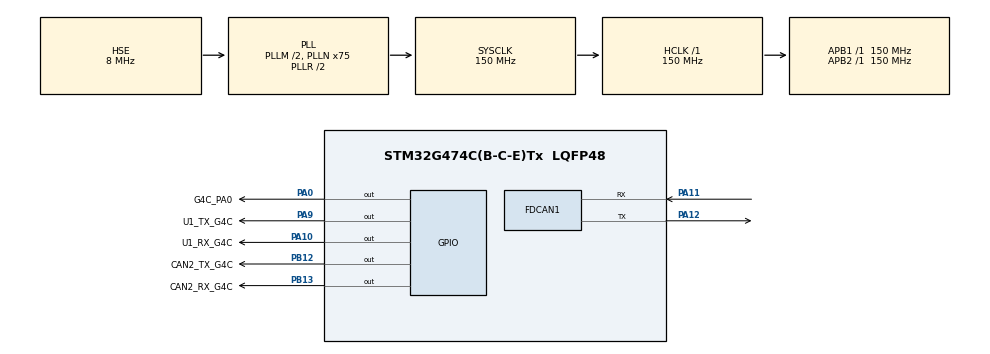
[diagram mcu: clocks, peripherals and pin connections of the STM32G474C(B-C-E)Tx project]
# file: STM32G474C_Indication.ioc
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FDCAN1.AutoRetransmission=DISABLE
FDCAN1.CalculateBaudRateNominal=1000000
FDCAN1.CalculateTimeBitNominal=1000
FDCAN1.CalculateTimeQuantumNominal=100.0
FDCAN1.DataPrescaler=4
FDCAN1.DataSyncJumpWidth=10
FDCAN1.DataTimeSeg1=10
FDCAN1.DataTimeSeg2=5
FDCAN1.ExtFiltersNbr=8
FDCAN1.FrameFormat=FDCAN_FRAME_FD_NO_BRS
FDCAN1.Mode=FDCAN_MODE_NORMAL
FDCAN1.NominalPrescaler=15
FDCAN1.NominalSyncJumpWidth=10
FDCAN1.NominalTimeSeg1=5
FDCAN1.NominalTimeSeg2=4
FDCAN1.StdFiltersNbr=16
Mcu.Family=STM32G4
Mcu.Name=STM32G474C(B-C-E)Tx
Mcu.Package=LQFP48
NVIC.FDCAN1_IT0_IRQn=true\:0\:0\:false\:false\:true\:true\:true\:true
NVIC.FDCAN1_IT1_IRQn=true\:0\:0\:false\:false\:true\:true\:true\:true
NVIC.PriorityGroup=NVIC_PRIORITYGROUP_4
PA0.GPIO_Label=G4C_PA0
PA0.GPIO_Speed=GPIO_SPEED_FREQ_HIGH
PA0.PinState=GPIO_PIN_SET
PA0.Signal=GPIO_Output
PA10.GPIO_Label=U1_RX_G4C
PA10.GPIO_Speed=GPIO_SPEED_FREQ_HIGH
PA10.PinState=GPIO_PIN_SET
PA10.Signal=GPIO_Output
PA11.Mode=FDCAN_Activate
PA11.Signal=FDCAN1_RX
PA12.Mode=FDCAN_Activate
PA12.Signal=FDCAN1_TX
PA13.Mode=Serial_Wire
PA13.Signal=SYS_JTMS-SWDIO
PA14.Mode=Serial_Wire
PA14.Signal=SYS_JTCK-SWCLK
PA9.GPIO_Label=U1_TX_G4C
PA9.GPIO_Speed=GPIO_SPEED_FREQ_HIGH
PA9.PinState=GPIO_PIN_SET
PA9.Signal=GPIO_Output
PB12.GPIO_Label=CAN2_TX_G4C
PB12.GPIO_Speed=GPIO_SPEED_FREQ_HIGH
PB12.PinState=GPIO_PIN_SET
PB12.Signal=GPIO_Output
PB13.GPIO_Label=CAN2_RX_G4C
PB13.GPIO_Speed=GPIO_SPEED_FREQ_HIGH
PB13.PinState=GPIO_PIN_SET
PB13.Signal=GPIO_Output
PF0-OSC_IN.Mode=HSE-External-Oscillator
PF0-OSC_IN.Signal=RCC_OSC_IN
PF1-OSC_OUT.Mode=HSE-External-Oscillator
PF1-OSC_OUT.Signal=RCC_OSC_OUT
ProjectManager.HeapSize=0x200
ProjectManager.StackSize=0x400
ProjectManager.TargetToolchain=MDK-ARM V5.32
RCC.ADC12Freq_Value=150000000
RCC.ADC345Freq_Value=150000000
RCC.AHBFreq_Value=150000000
RCC.APB1Freq_Value=150000000
RCC.APB1TimFreq_Value=150000000
RCC.APB2Freq_Value=150000000
RCC.APB2TimFreq_Value=150000000
RCC.CortexFreq_Value=150000000
RCC.EXTERNAL_CLOCK_VALUE=12288000
RCC.HCLKFreq_Value=150000000
RCC.HSE_VALUE=8000000
RCC.HSI48_VALUE=48000000
RCC.HSI_VALUE=16000000
RCC.LSE_VALUE=32768
RCC.PLLM=RCC_PLLM_DIV2
RCC.PLLN=75
RCC.PLLSourceVirtual=RCC_PLLSOURCE_HSE
RCC.SYSCLKFreq_VALUE=150000000
RCC.SYSCLKSource=RCC_SYSCLKSOURCE_PLLCLK
RCC.USBFreq_Value=150000000
RCC.VCOOutputFreq_Value=300000000
VP_SYS_VS_DBSignals.Mode=DisableDeadBatterySignals
board=custom

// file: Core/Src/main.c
/* USER CODE BEGIN Header */
/**
  ******************************************************************************
  * @file           : main.c
  * @brief          : Main program body
  ******************************************************************************
  * @attention
  *
  * Copyright (c) 2025 STMicroelectronics.
  * All rights reserved.
  *
  * This software is licensed under terms that can be found in the LICENSE file
  * in the root directory of this software component.
  * If no LICENSE file comes with this software, it is provided AS-IS.
  *
  ******************************************************************************
  */
/* USER CODE END Header */
#include "main.h"
#include "fdcan.h"
#include "gpio.h"

/* USER CODE BEGIN Includes */
#include "can_process.h"

/* USER CODE END Includes */

void SystemClock_Config(void);

int main(void)
{

  /* MCU Configuration--------------------------------------------------------*/

  /* Reset of all peripherals, Initializes the Flash interface and the Systick. */
  HAL_Init();

  /* Configure the system clock */
  SystemClock_Config();

  /* Initialize all configured peripherals */
  MX_GPIO_Init();
  MX_FDCAN1_Init();
  /* USER CODE BEGIN 2 */
  FDCAN1_Config();
  //GPIO初始�?

  HAL_GPIO_WritePin(G4C_PA0_GPIO_Port, G4C_PA0_Pin, GPIO_PIN_SET);//单片机指示灯

  //状�?�指示灯
  HAL_GPIO_WritePin(U1_RX_G4C_GPIO_Port, U1_RX_G4C_Pin, GPIO_PIN_SET);
  HAL_GPIO_WritePin(U1_TX_G4C_GPIO_Port, U1_TX_G4C_Pin, GPIO_PIN_SET);
  HAL_GPIO_WritePin(CAN2_RX_G4C_GPIO_Port, CAN2_RX_G4C_Pin, GPIO_PIN_SET);
  HAL_GPIO_WritePin(CAN2_TX_G4C_GPIO_Port, CAN2_TX_G4C_Pin, GPIO_PIN_SET);
  /* USER CODE END 2 */

  /* Infinite loop */
  while (1)
  {

    }
}

void SystemClock_Config(void)
{
  RCC_OscInitTypeDef RCC_OscInitStruct = {0};
  RCC_ClkInitTypeDef RCC_ClkInitStruct = {0};

  /** Configure the main internal regulator output voltage
  */
  HAL_PWREx_ControlVoltageScaling(PWR_REGULATOR_VOLTAGE_SCALE1);

  /** Initializes the RCC Oscillators according to the specified parameters
  * in the RCC_OscInitTypeDef structure.
  */
  RCC_OscInitStruct.OscillatorType = RCC_OSCILLATORTYPE_HSE;
  RCC_OscInitStruct.HSEState = RCC_HSE_ON;
  RCC_OscInitStruct.PLL.PLLState = RCC_PLL_ON;
  RCC_OscInitStruct.PLL.PLLSource = RCC_PLLSOURCE_HSE;
  RCC_OscInitStruct.PLL.PLLM = RCC_PLLM_DIV2;
  RCC_OscInitStruct.PLL.PLLN = 75;
  RCC_OscInitStruct.PLL.PLLP = RCC_PLLP_DIV2;
  RCC_OscInitStruct.PLL.PLLQ = RCC_PLLQ_DIV2;
  RCC_OscInitStruct.PLL.PLLR = RCC_PLLR_DIV2;
  if (HAL_RCC_OscConfig(&RCC_OscInitStruct) != HAL_OK)
  {
    Error_Handler();
  }

  /** Initializes the CPU, AHB and APB buses clocks
  */
  RCC_ClkInitStruct.ClockType = RCC_CLOCKTYPE_HCLK|RCC_CLOCKTYPE_SYSCLK
                              |RCC_CLOCKTYPE_PCLK1|RCC_CLOCKTYPE_PCLK2;
  RCC_ClkInitStruct.SYSCLKSource = RCC_SYSCLKSOURCE_PLLCLK;
  RCC_ClkInitStruct.AHBCLKDivider = RCC_SYSCLK_DIV1;
  RCC_ClkInitStruct.APB1CLKDivider = RCC_HCLK_DIV1;
  RCC_ClkInitStruct.APB2CLKDivider = RCC_HCLK_DIV1;

  if (HAL_RCC_ClockConfig(&RCC_ClkInitStruct, FLASH_LATENCY_4) != HAL_OK)
  {
    Error_Handler();
  }
}

void Error_Handler(void)
{
  __disable_irq();
  while (1)
  {
  }
}
